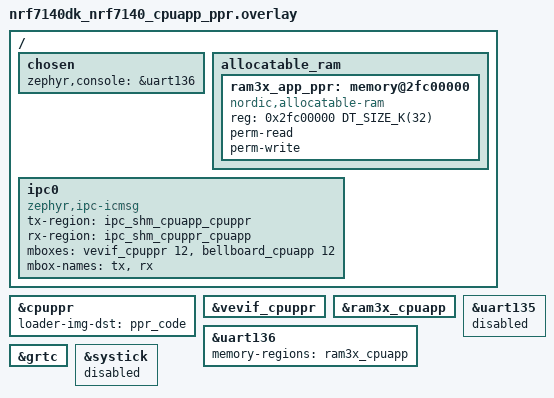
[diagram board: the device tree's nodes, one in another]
/*
 * Copyright (c) 2023 Nordic Semiconductor ASA
 *
 * SPDX-License-Identifier: LicenseRef-Nordic-5-Clause
 */

/ {
	chosen {
		zephyr,console = &uart136;
	};

	allocatable_ram {
		#address-cells = <1>;
		#size-cells = <1>;

		/* Configure RAM region.
		 * This is done to ensure correct UICR generation.
		 */
		ram3x_app_ppr: memory@2fc00000 {
			compatible = "nordic,allocatable-ram";
			reg = <0x2fc00000 DT_SIZE_K(32)>;
			perm-read;
			perm-write;
		};
	};

	ipc0: ipc0 {
		compatible = "zephyr,ipc-icmsg";
		tx-region = <&ipc_shm_cpuapp_cpuppr>;
		rx-region = <&ipc_shm_cpuppr_cpuapp>;
		mboxes = <&vevif_cpuppr 12>,
			 <&bellboard_cpuapp  12>;
		mbox-names = "tx", "rx";
		status = "okay";
	};
};

&cpuppr {
	loader-img-dst = <&ppr_code>;
	status = "okay";
};

&vevif_cpuppr {
       status = "okay";
};

&ram3x_cpuapp {
	status = "okay";
};

&uart136 {
	status = "okay";
	memory-regions = <&ram3x_cpuapp>;
};

&uart135 {
	status = "reserved";
};

&grtc {
	status = "okay";
};

&systick {
	status = "disabled";
};
